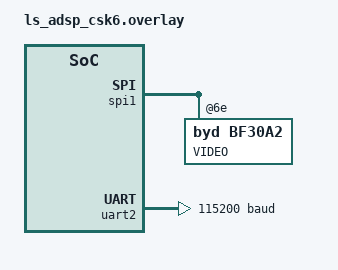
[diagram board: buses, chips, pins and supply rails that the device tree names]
&spi1 {
        pinctrl-0 = <&pinctrl_spi1_sclk_default &pinctrl_spi1_mosi_default &pinctrl_spi1_miso_default &pinctrl_spi1_cs_default>; 
        pinctrl-names = "default";
        status = "okay";
        spi-max-frequency = <25000000>;

        bf30a2: bf30a2@6e {
            compatible = "byd,bf30a2";
            status = "okay";
            label = "VIDEO";
            reg = <0x6e>;
            csk6-spec;
    };
};

&uart2 {
	current-speed = <115200>;
    pinctrl-0 = <&pinctrl_uart2_rx_default &pinctrl_uart2_tx_default>; 
    pinctrl-names = "default";
	status = "okay";
};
